VERSION "HIPBNYYYYYYYYYYYYYYYYYYYYYYYYYYYYYYYYYYYYY/4/%%%/4/'%**4YYY///"

NS_ :

BS_:

BU_: INV BMS VCU BMS Third_Party_Device BMS Third_Party_Device

BO_ 3221225472 VECTOR__INDEPENDENT_SIG_MSG: 0 Vector__XXX
 SG_ Thermistor_Module_Number : 0|8@1+ (1,0) [0|0] "" Vector__XXX
 SG_ Lowest_Thermistor_Value : 8|8@1- (1,0) [0|0] "c" Vector__XXX
 SG_ Highest_Thermistor_Value : 16|8@1- (1,0) [0|0] "c" Vector__XXX
 SG_ Average_Thermistor_Value : 24|8@1- (1,0) [0|0] "c" Vector__XXX
 SG_ Number_Thermistors_Enabled : 32|8@1+ (1,0) [0|0] "" Vector__XXX
 SG_ Highest_Thermistor_ID : 40|8@1+ (1,0) [0|0] "" Vector__XXX
 SG_ Lowest_Thermistor_ID : 48|8@1+ (1,0) [0|0] "" Vector__XXX
 SG_ Checksum : 56|8@1+ (1,0) [0|0] "" Vector__XXX
 SG_ Thermistor_Module_Number : 0|8@1+ (1,0) [0|0] "" Vector__XXX
 SG_ Lowest_Thermistor_Value : 8|8@1- (1,0) [0|0] "c" Vector__XXX
 SG_ Highest_Thermistor_Value : 16|8@1- (1,0) [0|0] "c" Vector__XXX
 SG_ Average_Thermistor_Value : 24|8@1- (1,0) [0|0] "c" Vector__XXX
 SG_ Number_Thermistors_Enabled : 32|8@1+ (1,0) [0|0] "" Vector__XXX
 SG_ Highest_Thermistor_ID : 40|8@1+ (1,0) [0|0] "" Vector__XXX
 SG_ Lowest_Thermistor_ID : 48|8@1+ (1,0) [0|0] "" Vector__XXX
 SG_ Checksum : 56|8@1+ (1,0) [0|0] "" Vector__XXX

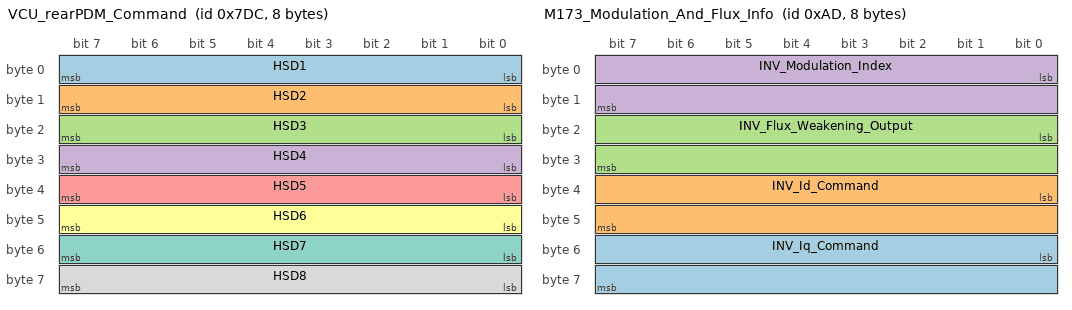
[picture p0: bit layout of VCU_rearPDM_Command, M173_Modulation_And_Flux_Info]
BO_ 2012 VCU_rearPDM_Command: 8 VCU
 SG_ HSD1 : 0|8@1+ (1,0) [0|1] "" Vector__XXX
 SG_ HSD2 : 8|8@1+ (1,0) [0|1] "" Vector__XXX
 SG_ HSD3 : 16|8@1+ (1,0) [0|1] "" Vector__XXX
 SG_ HSD4 : 24|8@1+ (1,0) [0|1] "" Vector__XXX
 SG_ HSD5 : 32|8@1+ (1,0) [0|1] "" Vector__XXX
 SG_ HSD6 : 40|8@1+ (1,0) [0|1] "" Vector__XXX
 SG_ HSD7 : 48|8@1+ (1,0) [0|1] "" Vector__XXX
 SG_ HSD8 : 56|8@1+ (1,0) [0|1] "" Vector__XXX

BO_ 173 M173_Modulation_And_Flux_Info: 8 INV
 SG_ INV_Iq_Command : 48|16@1- (0.1,0) [-3276.8|3276.7] "current:A" Vector__XXX
 SG_ INV_Id_Command : 32|16@1- (0.1,0) [-3276.8|3276.7] "current:A" Vector__XXX
 SG_ INV_Flux_Weakening_Output : 16|16@1- (0.1,0) [-3276.8|3276.7] "current:A" Vector__XXX
 SG_ INV_Modulation_Index : 0|16@1- (0.0001,0) [-3.2768|3.2767] "" Vector__XXX

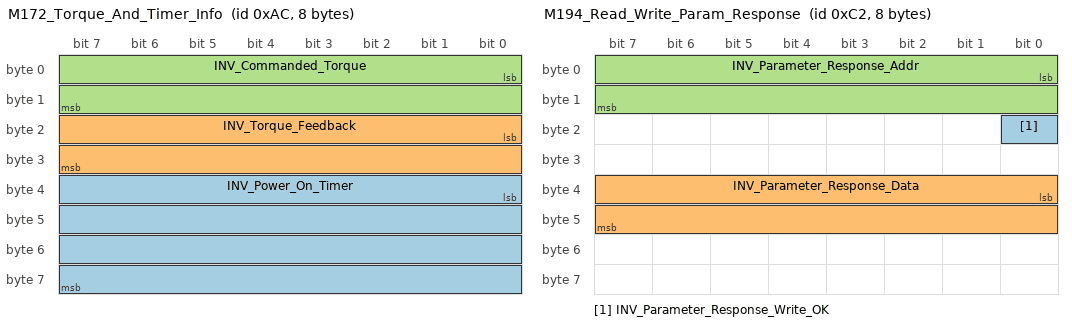
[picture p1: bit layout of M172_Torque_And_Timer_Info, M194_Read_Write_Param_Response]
BO_ 172 M172_Torque_And_Timer_Info: 8 INV
 SG_ INV_Power_On_Timer : 32|32@1+ (0.003,0) [0|12884800] "time:second" Vector__XXX
 SG_ INV_Torque_Feedback : 16|16@1- (0.1,0) [-3276.8|3276.7] "torque:N.m" Vector__XXX
 SG_ INV_Commanded_Torque : 0|16@1- (0.1,0) [-3276.8|3276.7] "torque:N.m" Vector__XXX

BO_ 194 M194_Read_Write_Param_Response: 8 INV
 SG_ INV_Parameter_Response_Write_OK : 16|1@1+ (1,0) [0|1] "" Vector__XXX
 SG_ INV_Parameter_Response_Data : 32|16@1- (1,0) [-32768|32767] "" Vector__XXX
 SG_ INV_Parameter_Response_Addr : 0|16@1+ (1,0) [0|65535] "" Vector__XXX

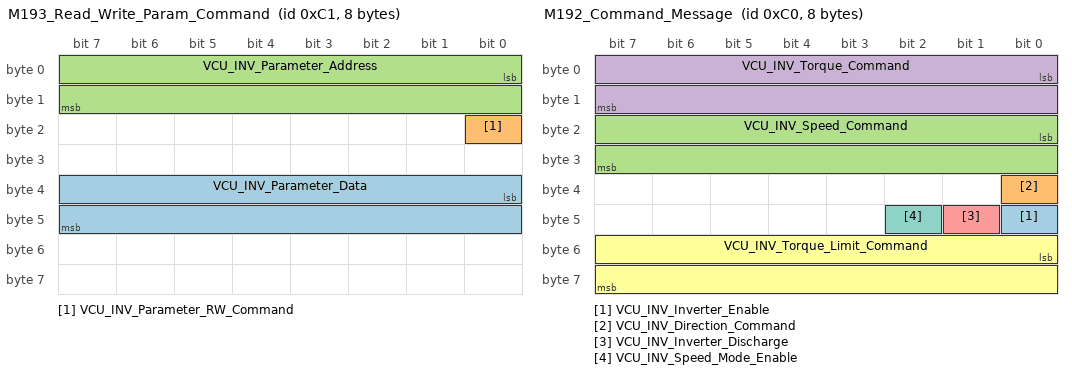
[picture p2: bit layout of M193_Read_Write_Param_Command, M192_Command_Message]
BO_ 193 M193_Read_Write_Param_Command: 8 VCU
 SG_ VCU_INV_Parameter_Data : 32|16@1- (1,0) [-32768|32767] "" Vector__XXX
 SG_ VCU_INV_Parameter_RW_Command : 16|1@1+ (1,0) [0|1] "" Vector__XXX
 SG_ VCU_INV_Parameter_Address : 0|16@1+ (1,0) [0|65535] "" Vector__XXX

BO_ 192 M192_Command_Message: 8 VCU
 SG_ VCU_INV_Inverter_Enable : 40|1@1+ (1,0) [0|1] "" Vector__XXX
 SG_ VCU_INV_Direction_Command : 32|1@1+ (1,0) [0|1] "" Vector__XXX
 SG_ VCU_INV_Speed_Command : 16|16@1- (1,0) [-32768|32767] "angular_speed:rpm" Vector__XXX
 SG_ VCU_INV_Torque_Command : 0|16@1- (0.1,0) [-3276.8|3276.7] "torque:N.m" Vector__XXX
 SG_ VCU_INV_Inverter_Discharge : 41|1@1+ (1,0) [0|1] "" Vector__XXX
 SG_ VCU_INV_Torque_Limit_Command : 48|16@1- (0.1,0) [-3276.8|3276.7] "torque:N.m" Vector__XXX
 SG_ VCU_INV_Speed_Mode_Enable : 42|1@1+ (1,0) [0|1] "" Vector__XXX

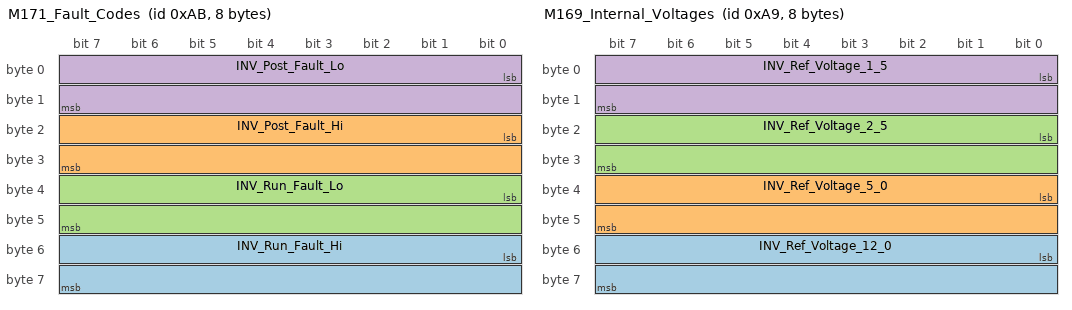
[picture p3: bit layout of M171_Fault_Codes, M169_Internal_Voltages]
BO_ 171 M171_Fault_Codes: 8 INV
 SG_ INV_Run_Fault_Hi : 48|16@1+ (1,0) [0|65535] "" Vector__XXX
 SG_ INV_Post_Fault_Hi : 16|16@1+ (1,0) [0|65535] "" Vector__XXX
 SG_ INV_Run_Fault_Lo : 32|16@1+ (1,0) [0|65535] "" Vector__XXX
 SG_ INV_Post_Fault_Lo : 0|16@1+ (1,0) [0|65535] "" Vector__XXX

BO_ 170 M170_Internal_States: 8 INV
 SG_ INV_Direction_Command : 56|1@1+ (1,0) [0|1] "" Vector__XXX
 SG_ INV_Inverter_Enable_State : 48|1@1+ (1,0) [0|1] "" Vector__XXX
 SG_ INV_Relay_3_Status : 26|1@1+ (1,0) [0|1] "" Vector__XXX
 SG_ INV_Relay_4_Status : 27|1@1+ (1,0) [0|1] "" Vector__XXX
 SG_ INV_Relay_2_Status : 25|1@1+ (1,0) [0|1] "" Vector__XXX
 SG_ INV_Inverter_Run_Mode : 32|1@1+ (1,0) [0|1] "" Vector__XXX
 SG_ INV_Inverter_Command_Mode : 40|1@1+ (1,0) [0|1] "" Vector__XXX
 SG_ INV_Relay_1_Status : 24|1@1+ (1,0) [0|1] "" Vector__XXX
 SG_ INV_Inverter_State : 16|8@1+ (1,0) [0|255] "" Vector__XXX
 SG_ INV_VSM_State : 0|8@1+ (1,0) [0|15] "" Vector__XXX
 SG_ INV_Inverter_Enable_Lockout : 55|1@1+ (1,0) [0|1] "" Vector__XXX
 SG_ INV_Inverter_Discharge_State : 37|3@1+ (1,0) [0|7] "" Vector__XXX
 SG_ INV_Relay_5_Status : 28|1@1+ (1,0) [0|1] "" Vector__XXX
 SG_ INV_Relay_6_Status : 29|1@1+ (1,0) [0|1] "" Vector__XXX
 SG_ INV_BMS_Active : 57|1@1+ (1,0) [0|1] "" Vector__XXX
 SG_ INV_BMS_Torque_Limiting : 58|1@1+ (1,0) [0|1] "" Vector__XXX
 SG_ INV_PWM_Frequency : 8|8@1+ (1,0) [0|255] "" Vector__XXX
 SG_ INV_Limit_Max_Speed : 59|1@1+ (1,0) [0|1] "" Vector__XXX
 SG_ INV_Limit_Hot_Spot : 60|1@1+ (1,0) [0|1] "" Vector__XXX
 SG_ INV_Low_Speed_Limiting : 61|1@1+ (1,0) [0|1] "" Vector__XXX
 SG_ INV_Rolling_Counter : 44|4@1+ (1,0) [0|15] "" Vector__XXX
 SG_ INV_Limit_Coolant_Derating : 62|1@1+ (1,0) [0|1] "" Vector__XXX
 SG_ INV_Self_Sensing_Assist_Enable : 33|1@1+ (1,0) [0|1] "" Vector__XXX
 SG_ INV_Limit_Stall_Burst_Model : 63|1@1+ (1,0) [0|1] "" Vector__XXX
 SG_ INV_Burst_Model_Mode : 49|1@1+ (1,0) [0|1] "" Vector__XXX
 SG_ INV_Key_Switch_Start_Status : 54|1@1+ (1,0) [0|1] "" Vector__XXX

BO_ 169 M169_Internal_Voltages: 8 INV
 SG_ INV_Ref_Voltage_12_0 : 48|16@1- (0.01,0) [-327.68|327.67] "voltage:V" Vector__XXX
 SG_ INV_Ref_Voltage_5_0 : 32|16@1- (0.01,0) [-327.68|327.67] "voltage:V" Vector__XXX
 SG_ INV_Ref_Voltage_2_5 : 16|16@1- (0.01,0) [-327.68|327.67] "voltage:V" Vector__XXX
 SG_ INV_Ref_Voltage_1_5 : 0|16@1- (0.01,0) [-327.68|327.67] "voltage:V" Vector__XXX

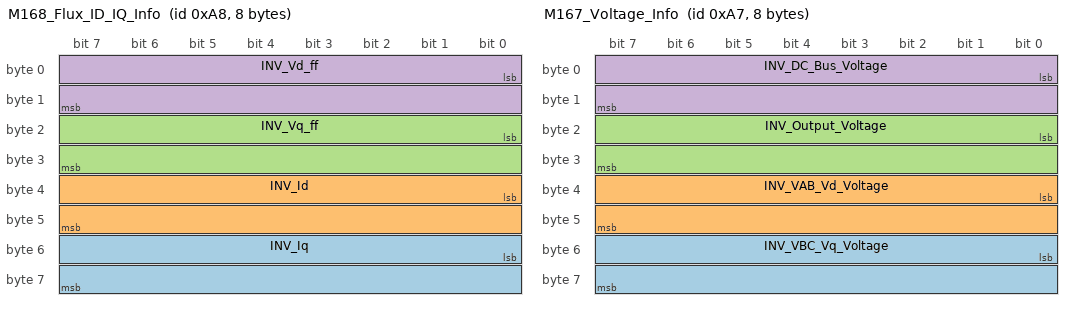
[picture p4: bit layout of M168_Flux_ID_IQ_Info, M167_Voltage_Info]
BO_ 168 M168_Flux_ID_IQ_Info: 8 INV
 SG_ INV_Iq : 48|16@1- (0.1,0) [-3276.8|3276.7] "current:A" Vector__XXX
 SG_ INV_Id : 32|16@1- (0.1,0) [-3276.8|3276.7] "current:A" Vector__XXX
 SG_ INV_Vq_ff : 16|16@1- (0.1,0) [-3276.7|3276.7] "voltage:V" Vector__XXX
 SG_ INV_Vd_ff : 0|16@1- (0.1,0) [-3276.7|3276.7] "voltage:V" Vector__XXX

BO_ 167 M167_Voltage_Info: 8 INV
 SG_ INV_VBC_Vq_Voltage : 48|16@1- (0.1,0) [-3276.8|3276.7] "voltage:V" Vector__XXX
 SG_ INV_VAB_Vd_Voltage : 32|16@1- (0.1,0) [-3276.8|3276.7] "voltage:V" Vector__XXX
 SG_ INV_Output_Voltage : 16|16@1- (0.1,0) [-3276.8|3276.7] "voltage:V" Vector__XXX
 SG_ INV_DC_Bus_Voltage : 0|16@1- (0.1,0) [-3276.8|3276.7] "voltage:V" Vector__XXX

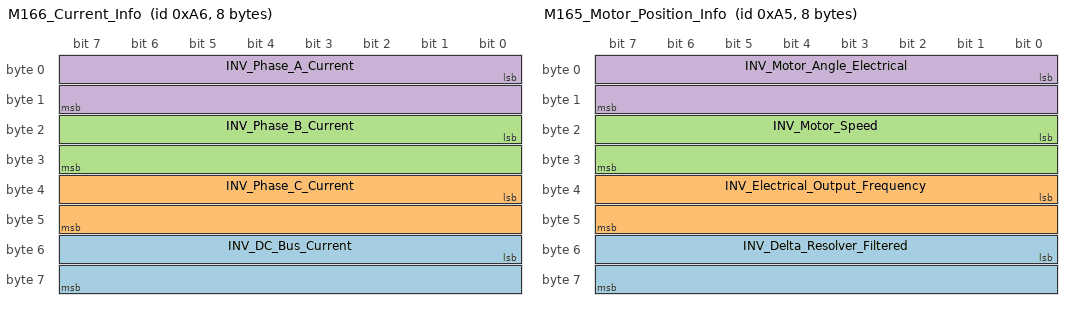
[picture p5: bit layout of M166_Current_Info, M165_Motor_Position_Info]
BO_ 166 M166_Current_Info: 8 INV
 SG_ INV_DC_Bus_Current : 48|16@1- (0.1,0) [-3276.8|3276.7] "current:A" Vector__XXX
 SG_ INV_Phase_C_Current : 32|16@1- (0.1,0) [-3276.8|3276.7] "current:A" Vector__XXX
 SG_ INV_Phase_B_Current : 16|16@1- (0.1,0) [-3276.8|3276.7] "current:A" Vector__XXX
 SG_ INV_Phase_A_Current : 0|16@1- (0.1,0) [-3276.8|3276.7] "current:A" Vector__XXX

BO_ 165 M165_Motor_Position_Info: 8 INV
 SG_ INV_Delta_Resolver_Filtered : 48|16@1- (0.1,0) [-3276.8|3276.7] "angle:deg" Vector__XXX
 SG_ INV_Electrical_Output_Frequency : 32|16@1- (0.1,0) [-3276.8|3276.7] "frequency:Hz" Vector__XXX
 SG_ INV_Motor_Speed : 16|16@1- (1,0) [-32768|32767] "angular_speed:rpm" Vector__XXX
 SG_ INV_Motor_Angle_Electrical : 0|16@1+ (0.1,0) [0|6553.5] "angle:deg" Vector__XXX

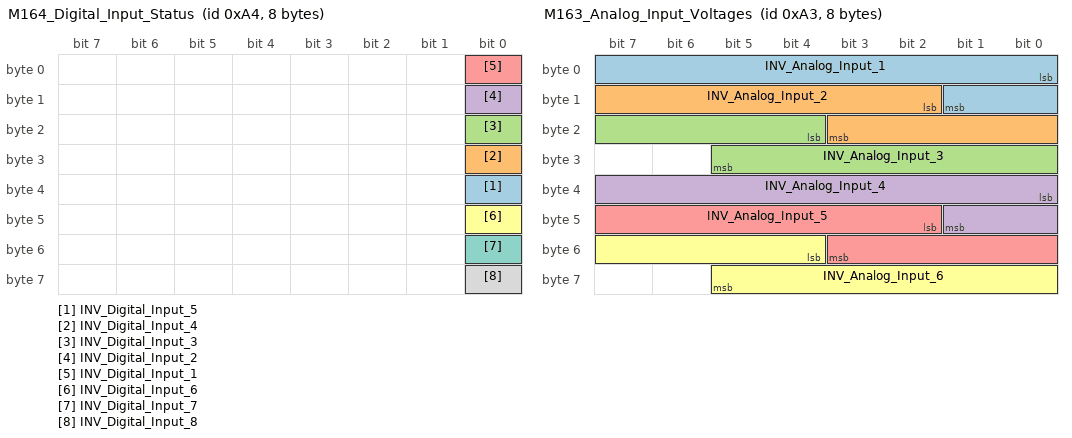
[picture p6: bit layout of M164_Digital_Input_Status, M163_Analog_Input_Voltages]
BO_ 164 M164_Digital_Input_Status: 8 INV
 SG_ INV_Digital_Input_5 : 32|1@1+ (1,0) [0|1] "" Vector__XXX
 SG_ INV_Digital_Input_4 : 24|1@1+ (1,0) [0|1] "" Vector__XXX
 SG_ INV_Digital_Input_3 : 16|1@1+ (1,0) [0|1] "" Vector__XXX
 SG_ INV_Digital_Input_2 : 8|1@1+ (1,0) [0|1] "" Vector__XXX
 SG_ INV_Digital_Input_1 : 0|1@1+ (1,0) [0|1] "" Vector__XXX
 SG_ INV_Digital_Input_6 : 40|1@1+ (1,0) [0|1] "" Vector__XXX
 SG_ INV_Digital_Input_7 : 48|1@1+ (1,0) [0|1] "" Vector__XXX
 SG_ INV_Digital_Input_8 : 56|1@1+ (1,0) [0|1] "" Vector__XXX

BO_ 163 M163_Analog_Input_Voltages: 8 INV
 SG_ INV_Analog_Input_1 : 0|10@1+ (0.01,0) [0|10.23] "voltage:V" Vector__XXX
 SG_ INV_Analog_Input_2 : 10|10@1+ (0.01,0) [0|10.23] "voltage:V" Vector__XXX
 SG_ INV_Analog_Input_3 : 20|10@1+ (0.01,0) [0|10.23] "voltage:V" Vector__XXX
 SG_ INV_Analog_Input_4 : 32|10@1+ (0.01,0) [0|10.23] "voltage:V" Vector__XXX
 SG_ INV_Analog_Input_5 : 42|10@1+ (0.01,0) [0|10.23] "voltage:V" Vector__XXX
 SG_ INV_Analog_Input_6 : 52|10@1+ (0.01,0) [0|10.23] "voltage:V" Vector__XXX

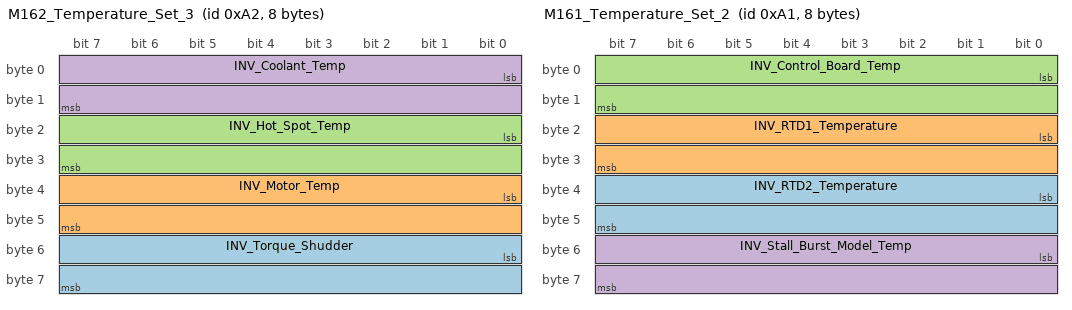
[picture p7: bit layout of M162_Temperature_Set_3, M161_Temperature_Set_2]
BO_ 162 M162_Temperature_Set_3: 8 INV
 SG_ INV_Torque_Shudder : 48|16@1- (0.1,0) [-3276.8|3276.7] "torque:N.m" Vector__XXX
 SG_ INV_Motor_Temp : 32|16@1- (0.1,0) [-3276.8|3276.7] "temperature:C" Vector__XXX
 SG_ INV_Hot_Spot_Temp : 16|16@1- (0.1,0) [-3276.8|3276.7] "temperature:C" Vector__XXX
 SG_ INV_Coolant_Temp : 0|16@1- (0.1,0) [-3276.8|3276.7] "temperature:C" Vector__XXX

BO_ 161 M161_Temperature_Set_2: 8 INV
 SG_ INV_RTD2_Temperature : 32|16@1- (0.1,0) [-3276.8|3276.7] "temperature:C" Vector__XXX
 SG_ INV_RTD1_Temperature : 16|16@1- (0.1,0) [-3276.8|3276.7] "temperature:C" Vector__XXX
 SG_ INV_Control_Board_Temp : 0|16@1- (0.1,0) [-3276.8|3276.7] "temperature:C" Vector__XXX
 SG_ INV_Stall_Burst_Model_Temp : 48|16@1- (0.1,0) [-3276.8|3276.7] "temperature:C" Vector__XXX

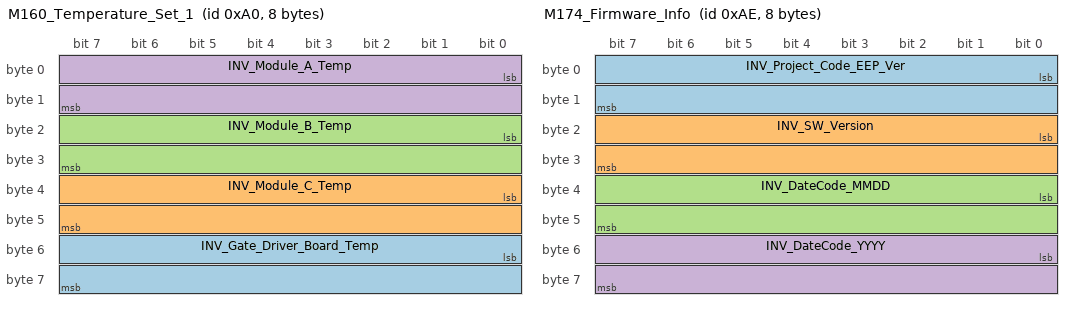
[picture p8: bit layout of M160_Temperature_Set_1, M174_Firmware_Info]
BO_ 160 M160_Temperature_Set_1: 8 INV
 SG_ INV_Gate_Driver_Board_Temp : 48|16@1- (0.1,0) [-3276.8|3276.7] "temperature:C" Vector__XXX
 SG_ INV_Module_C_Temp : 32|16@1- (0.1,0) [-3276.8|3276.7] "temperature:C" Vector__XXX
 SG_ INV_Module_B_Temp : 16|16@1- (0.1,0) [-3276.8|3276.7] "temperature:C" Vector__XXX
 SG_ INV_Module_A_Temp : 0|16@1- (0.1,0) [-3276.8|3276.7] "temperature:C" Vector__XXX

BO_ 174 M174_Firmware_Info: 8 INV
 SG_ INV_Project_Code_EEP_Ver : 0|16@1+ (1,0) [0|65535] "" Vector__XXX
 SG_ INV_SW_Version : 16|16@1+ (1,0) [0|65535] "" Vector__XXX
 SG_ INV_DateCode_MMDD : 32|16@1+ (1,0) [0|65535] "" Vector__XXX
 SG_ INV_DateCode_YYYY : 48|16@1+ (1,0) [0|65535] "" Vector__XXX

BO_ 175 M175_Diag_Data_Message: 8 INV
 SG_ INV_Diag_Record : 0|8@1+ (1,0) [0|160] "" Vector__XXX
 SG_ INV_Diag_Segment M : 8|8@1+ (1,0) [0|5] "" Vector__XXX
 SG_ INV_Diag_Gamma_Resolver m0 : 16|16@1- (0.1,0) [0|360] "angle:deg" Vector__XXX
 SG_ INV_Diag_Gamma_Observer m0 : 32|16@1- (0.1,0) [0|360] "angle:deg" Vector__XXX
 SG_ INV_Diag_Sin_Used m0 : 48|16@1- (1,0) [-5|5] "voltage:V" Vector__XXX
 SG_ INV_Diag_Cos_Used m1 : 16|16@1- (1,0) [-5|5] "voltage:V" Vector__XXX
 SG_ INV_Diag_Ia m1 : 32|16@1- (0.1,0) [-2000|2000] "current:A" Vector__XXX
 SG_ INV_Diag_Ib m1 : 48|16@1- (0.1,0) [-2000|2000] "current:A" Vector__XXX
 SG_ INV_Diag_Ic m2 : 16|16@1- (0.1,0) [-2000|2000] "current:A" Vector__XXX
 SG_ INV_Diag_Vdc m2 : 32|16@1- (0.1,0) [0|1000] "voltage:V" Vector__XXX
 SG_ INV_Diag_Iq_cmd m2 : 48|16@1- (0.1,0) [-2000|2000] "current:A" Vector__XXX
 SG_ INV_Diag_Id_cmd m3 : 16|16@1- (0.1,0) [-2000|2000] "current:A" Vector__XXX
 SG_ INV_Diag_Mod_Index m3 : 32|16@1- (0.0001,0) [0|2] "" Vector__XXX
 SG_ INV_Diag_FW_Output m3 : 48|16@1- (0.1,0) [-2000|2000] "current:A" Vector__XXX
 SG_ INV_Diag_Vq_Cmd m4 : 16|16@1- (0.1,0) [-1000|1000] "voltage:V" Vector__XXX
 SG_ INV_Diag_Vd_Cmd m4 : 32|16@1- (0.1,0) [-1000|1000] "voltage:V" Vector__XXX
 SG_ INV_Diag_Vqs_Cmd m4 : 48|16@1- (0.1,0) [-1000|1000] "voltage:V" Vector__XXX
 SG_ INV_Diag_PWM_Freq m5 : 16|16@1+ (1,0) [0|24] "frequency:kHz" Vector__XXX
 SG_ INV_Diag_Run_Faults_Lo m5 : 32|16@1+ (1,0) [0|65535] "" Vector__XXX
 SG_ INV_Diag_Run_Faults_Hi m5 : 48|16@1+ (1,0) [0|65535] "" Vector__XXX

BO_ 514 BMS_Current_Limit: 8 BMS
 SG_ BMS_Max_Discharge_Current : 0|16@1+ (1,0) [0|1000] "current:A" Vector__XXX
 SG_ BMS_Max_Charge_Current : 16|16@1+ (1,0) [0|1000] "current:A" Vector__XXX

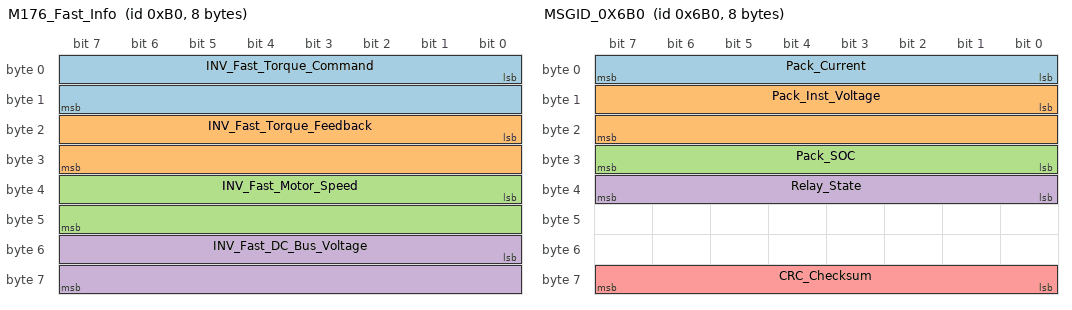
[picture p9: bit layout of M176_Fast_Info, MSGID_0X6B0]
BO_ 176 M176_Fast_Info: 8 INV
 SG_ INV_Fast_Torque_Command : 0|16@1- (0.1,0) [-3276.8|32767.7] "torque:N.m" Vector__XXX
 SG_ INV_Fast_Torque_Feedback : 16|16@1- (0.1,0) [-3276.8|3276.7] "torque:N.m" Vector__XXX
 SG_ INV_Fast_Motor_Speed : 32|16@1- (1,0) [-32768|32767] "angular_speed:rpm" Vector__XXX
 SG_ INV_Fast_DC_Bus_Voltage : 48|16@1- (0.1,0) [-3276.8|3276.7] "voltage:V" Vector__XXX

BO_ 1712 MSGID_0X6B0: 8 BMS
 SG_ Pack_Current : 0|8@1+ (0.1,0) [0|0] "Amps"  Third_Party_Device
 SG_ Pack_Inst_Voltage : 8|16@1+ (0.1,0) [0|0] "Volts"  Third_Party_Device
 SG_ Pack_SOC : 24|8@1+ (0.5,0) [0|0] "Percent"  Third_Party_Device
 SG_ Relay_State : 32|8@1+ (1,0) [0|0] ""  Third_Party_Device
 SG_ CRC_Checksum : 56|8@1+ (1,1720) [0|0] ""  Third_Party_Device

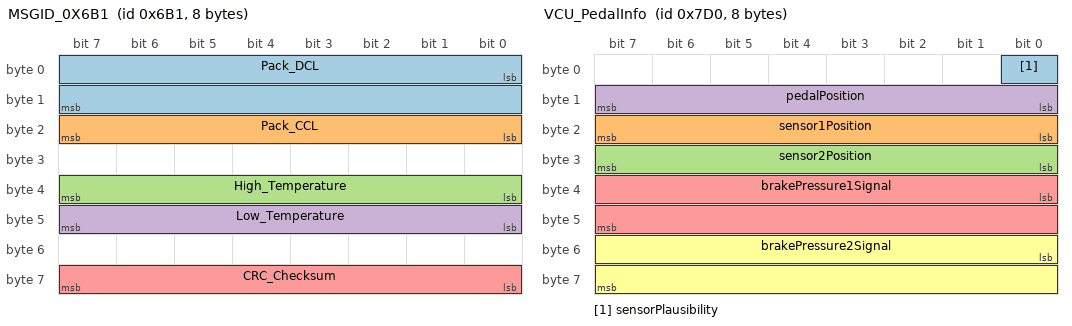
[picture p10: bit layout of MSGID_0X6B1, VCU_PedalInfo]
BO_ 1713 MSGID_0X6B1: 8 BMS
 SG_ Pack_DCL : 0|16@1+ (1,0) [0|0] "Amps"  Third_Party_Device
 SG_ Pack_CCL : 16|8@1+ (1,0) [0|0] "Amps"  Third_Party_Device
 SG_ High_Temperature : 32|8@1+ (1,0) [0|0] "Celsius"  Third_Party_Device
 SG_ Low_Temperature : 40|8@1+ (1,0) [0|0] "Celsius"  Third_Party_Device
 SG_ CRC_Checksum : 56|8@1+ (1,1721) [0|0] ""  Third_Party_Device

BO_ 1714 MSGID_0X6B2: 4 BMS
 SG_ DTC_Flags_1 : 7|16@0+ (1,0) [0|0] ""  Third_Party_Device
 SG_ DTC_Flags_2 : 23|16@0+ (1,0) [0|0] ""  Third_Party_Device

BO_ 2000 VCU_PedalInfo: 8 VCU
 SG_ sensorPlausibility : 0|1@1+ (1,0) [2|1] "" Vector__XXX
 SG_ sensor1Position : 16|8@1+ (1,0) [0|100] "" Vector__XXX
 SG_ sensor2Position : 24|8@1+ (1,0) [0|100] "" Vector__XXX
 SG_ pedalPosition : 8|8@1+ (1,0) [0|100] "" Vector__XXX
 SG_ brakePressure1Signal : 32|16@1+ (0.01,0) [0|5] "" Vector__XXX
 SG_ brakePressure2Signal : 48|16@1+ (0.01,0) [0|5] "" Vector__XXX

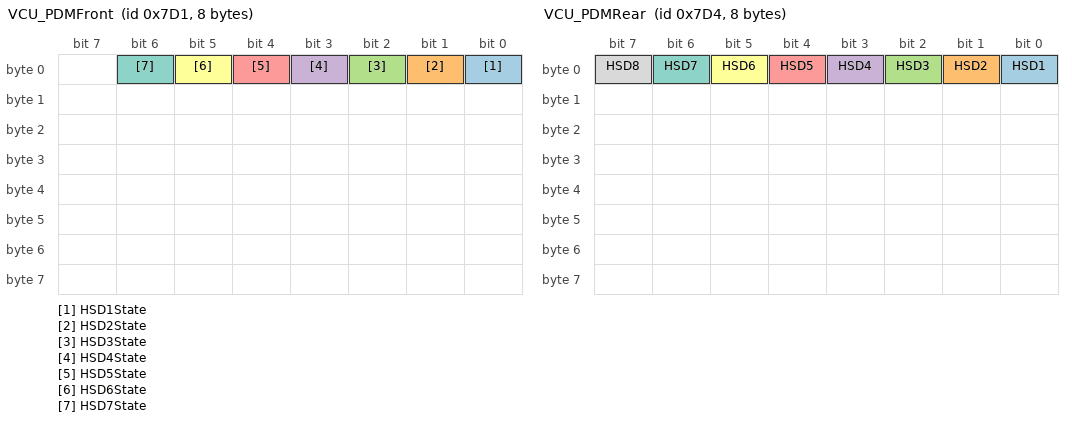
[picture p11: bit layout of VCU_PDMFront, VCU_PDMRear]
BO_ 2001 VCU_PDMFront: 8 VCU
 SG_ HSD1State : 0|1@1+ (1,0) [0|1] "" Vector__XXX
 SG_ HSD2State : 1|1@1+ (1,0) [0|0] "" Vector__XXX
 SG_ HSD3State : 2|1@1+ (1,0) [0|0] "" Vector__XXX
 SG_ HSD4State : 3|1@1+ (1,0) [0|0] "" Vector__XXX
 SG_ HSD5State : 4|1@1+ (1,0) [0|0] "" Vector__XXX
 SG_ HSD6State : 5|1@1+ (1,0) [0|0] "" Vector__XXX
 SG_ HSD7State : 6|1@1+ (1,0) [0|0] "" Vector__XXX

BO_ 2002 VCU_State_Info: 8 VCU
 SG_ State : 8|8@1+ (1,0) [0|6] "" Vector__XXX
 SG_ RTD_Button : 0|1@1+ (1,0) [0|1] "" Vector__XXX

BO_ 2003 VCU_Precharge: 8 VCU
 SG_ Precharge_Enable : 0|1@1+ (1,0) [0|1] "" Vector__XXX
 SG_ Precharge_OK : 1|1@1+ (1,0) [0|1] "" Vector__XXX

BO_ 2004 VCU_PDMRear: 8 VCU
 SG_ HSD1 : 0|1@1+ (1,0) [0|1] "" Vector__XXX
 SG_ HSD2 : 1|1@1+ (1,0) [0|1] "" Vector__XXX
 SG_ HSD3 : 2|1@1+ (1,0) [0|1] "" Vector__XXX
 SG_ HSD4 : 3|1@1+ (1,0) [0|1] "" Vector__XXX
 SG_ HSD5 : 4|1@1+ (1,0) [0|1] "" Vector__XXX
 SG_ HSD6 : 5|1@1+ (1,0) [0|1] "" Vector__XXX
 SG_ HSD7 : 6|1@1+ (1,0) [0|1] "" Vector__XXX
 SG_ HSD8 : 7|1@1+ (1,0) [0|0] "" Vector__XXX

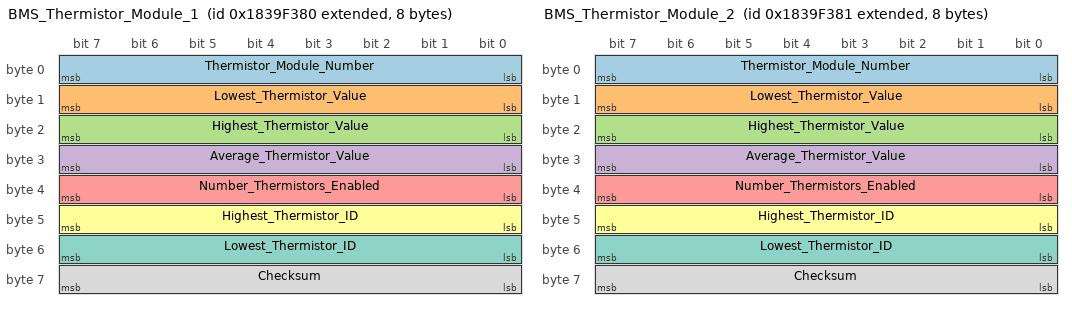
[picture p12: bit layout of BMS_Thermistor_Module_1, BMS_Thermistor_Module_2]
BO_ 2553934720 BMS_Thermistor_Module_1: 8 BMS
 SG_ Thermistor_Module_Number : 0|8@1+ (1,0) [0|0] "" Vector__XXX
 SG_ Lowest_Thermistor_Value : 8|8@1- (1,0) [0|0] "c" Vector__XXX
 SG_ Highest_Thermistor_Value : 16|8@1- (1,0) [0|0] "c" Vector__XXX
 SG_ Average_Thermistor_Value : 24|8@1- (1,0) [0|0] "c" Vector__XXX
 SG_ Number_Thermistors_Enabled : 32|8@1+ (1,0) [0|0] "" Vector__XXX
 SG_ Highest_Thermistor_ID : 40|8@1+ (1,0) [0|0] "" Vector__XXX
 SG_ Lowest_Thermistor_ID : 48|8@1+ (1,0) [0|0] "" Vector__XXX
 SG_ Checksum : 56|8@1+ (1,0) [0|0] "" Vector__XXX

BO_ 2553934721 BMS_Thermistor_Module_2: 8 BMS
 SG_ Thermistor_Module_Number : 0|8@1+ (1,0) [0|0] "" Vector__XXX
 SG_ Lowest_Thermistor_Value : 8|8@1- (1,0) [0|0] "c" Vector__XXX
 SG_ Highest_Thermistor_Value : 16|8@1- (1,0) [0|0] "c" Vector__XXX
 SG_ Average_Thermistor_Value : 24|8@1- (1,0) [0|0] "c" Vector__XXX
 SG_ Number_Thermistors_Enabled : 32|8@1+ (1,0) [0|0] "" Vector__XXX
 SG_ Highest_Thermistor_ID : 40|8@1+ (1,0) [0|0] "" Vector__XXX
 SG_ Lowest_Thermistor_ID : 48|8@1+ (1,0) [0|0] "" Vector__XXX
 SG_ Checksum : 56|8@1+ (1,0) [0|0] "" Vector__XXX

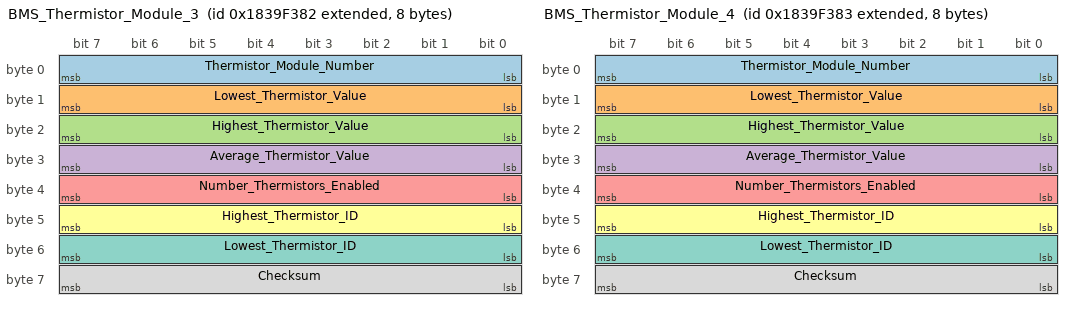
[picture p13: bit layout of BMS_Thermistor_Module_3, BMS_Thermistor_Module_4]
BO_ 2553934722 BMS_Thermistor_Module_3: 8 BMS
 SG_ Thermistor_Module_Number : 0|8@1+ (1,0) [0|0] "" Vector__XXX
 SG_ Lowest_Thermistor_Value : 8|8@1- (1,0) [0|0] "c" Vector__XXX
 SG_ Highest_Thermistor_Value : 16|8@1- (1,0) [0|0] "c" Vector__XXX
 SG_ Average_Thermistor_Value : 24|8@1- (1,0) [0|0] "c" Vector__XXX
 SG_ Number_Thermistors_Enabled : 32|8@1+ (1,0) [0|0] "" Vector__XXX
 SG_ Highest_Thermistor_ID : 40|8@1+ (1,0) [0|0] "" Vector__XXX
 SG_ Lowest_Thermistor_ID : 48|8@1+ (1,0) [0|0] "" Vector__XXX
 SG_ Checksum : 56|8@1+ (1,0) [0|0] "" Vector__XXX

BO_ 2553934723 BMS_Thermistor_Module_4: 8 BMS
 SG_ Thermistor_Module_Number : 0|8@1+ (1,0) [0|0] "" Vector__XXX
 SG_ Lowest_Thermistor_Value : 8|8@1- (1,0) [0|0] "c" Vector__XXX
 SG_ Highest_Thermistor_Value : 16|8@1- (1,0) [0|0] "c" Vector__XXX
 SG_ Average_Thermistor_Value : 24|8@1- (1,0) [0|0] "c" Vector__XXX
 SG_ Number_Thermistors_Enabled : 32|8@1+ (1,0) [0|0] "" Vector__XXX
 SG_ Highest_Thermistor_ID : 40|8@1+ (1,0) [0|0] "" Vector__XXX
 SG_ Lowest_Thermistor_ID : 48|8@1+ (1,0) [0|0] "" Vector__XXX
 SG_ Checksum : 56|8@1+ (1,0) [0|0] "" Vector__XXX

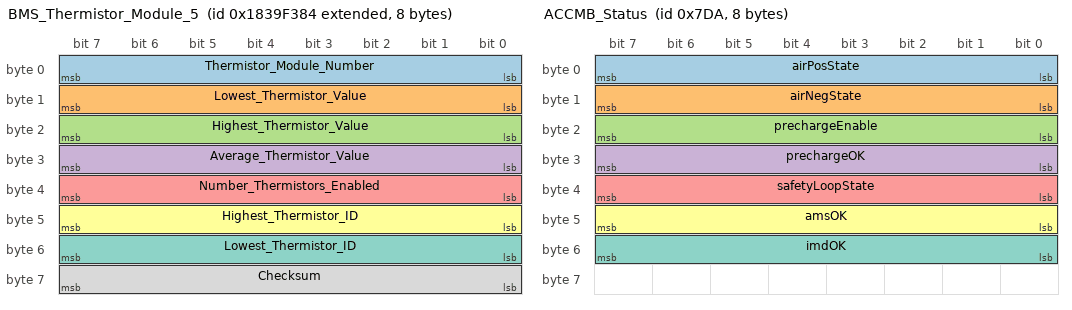
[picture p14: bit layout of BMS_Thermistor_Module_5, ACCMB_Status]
BO_ 2553934724 BMS_Thermistor_Module_5: 8 BMS
 SG_ Thermistor_Module_Number : 0|8@1+ (1,0) [0|0] "" Vector__XXX
 SG_ Lowest_Thermistor_Value : 8|8@1- (1,0) [0|0] "c" Vector__XXX
 SG_ Highest_Thermistor_Value : 16|8@1- (1,0) [0|0] "c" Vector__XXX
 SG_ Average_Thermistor_Value : 24|8@1- (1,0) [0|0] "c" Vector__XXX
 SG_ Number_Thermistors_Enabled : 32|8@1+ (1,0) [0|0] "" Vector__XXX
 SG_ Highest_Thermistor_ID : 40|8@1+ (1,0) [0|0] "" Vector__XXX
 SG_ Lowest_Thermistor_ID : 48|8@1+ (1,0) [0|0] "" Vector__XXX
 SG_ Checksum : 56|8@1+ (1,0) [0|0] "" Vector__XXX

BO_ 2010 ACCMB_Status: 8 BMS
 SG_ airPosState : 0|8@1+ (1,0) [0|0] "" Vector__XXX
 SG_ airNegState : 8|8@1+ (1,0) [0|0] "" Vector__XXX
 SG_ prechargeEnable : 16|8@1+ (1,0) [0|0] "" Vector__XXX
 SG_ prechargeOK : 24|8@1+ (1,0) [0|0] "" Vector__XXX
 SG_ safetyLoopState : 32|8@1+ (1,0) [0|0] "" Vector__XXX
 SG_ amsOK : 40|8@1+ (1,0) [0|0] "" Vector__XXX
 SG_ imdOK : 48|8@1+ (1,0) [0|0] "" Vector__XXX

BO_ 2011 VCU_BrakeLight: 1 VCU
 SG_ BrakeLightSignal : 0|1@1+ (1,0) [0|1] "" Vector__XXX

BO_ 2013 VCU_rearLinPots: 8 VCU

BO_ 2028 VCU_Front_Wheel_Left: 2 VCU
 SG_ Front_Left_Wheelspeed : 0|16@1+ (0.1,0) [0|6553.5] "RPM" Vector__XXX

BO_ 2029 VCU_Front_Wheel_Right: 2 VCU
 SG_ Front_Right_Wheelspeed : 0|16@1+ (0.1,0) [0|6553.5] "RPM" Vector__XXX

BO_ 177 M177_Torque_Capability: 8 INV
 SG_ INV_Torque_Capability : 0|16@1+ (0.1,0) [0|0] "" Vector__XXX

CM_ SG_ 173 INV_Iq_Command "The commanded Q-axis current";
CM_ SG_ 173 INV_Id_Command "The commanded D-axis current";
CM_ SG_ 173 INV_Flux_Weakening_Output "This is the current output of the flux regulator.";
CM_ SG_ 173 INV_Modulation_Index "This is the modulation index. The scale factor is x100. To get the actual modulation index divide the value by 100.";
CM_ SG_ 172 INV_Power_On_Timer "Updated every 3 msec. This will roll over in approximately 150 days!";
CM_ SG_ 172 INV_Torque_Feedback "Estimated motor torque feedback";
CM_ SG_ 172 INV_Commanded_Torque "The commanded Torque";
CM_ BO_ 194 "To write a parameter use message 0x0C1 with byte #2 set to 1 (write). 
To read a parameter use message 0x0C1 with byte #2 to set 0 (read). ";
CM_ SG_ 194 INV_Parameter_Response_Write_OK "0=Write failure, 1=Success";
CM_ SG_ 194 INV_Parameter_Response_Data "Data from parameter message.  All data is 16 bits and is contained in bytes 4 and 5. Bytes 6 and 7 should be ignored.";
CM_ SG_ 194 INV_Parameter_Response_Addr "Address of parameter response message data.";
CM_ BO_ 193 "To write a parameter use message 0x0C1 with byte #2 set to 1 (write). 
To read a parameter use message 0x0C1 with byte #2 to set 0 (read). ";
CM_ SG_ 193 VCU_INV_Parameter_Data "Data to be written.  All data is 16 bits and is contained in bytes 4 and 5.";
CM_ SG_ 193 VCU_INV_Parameter_RW_Command "0=Read, 1=Write";
CM_ SG_ 193 VCU_INV_Parameter_Address "Address of parameter to be written or read.";
CM_ BO_ 192 "The command message is used to transmit data to the controller. This message is sent from a user supplied external controller to the PMxxx controller.";
CM_ SG_ 192 VCU_INV_Inverter_Enable "0=Inverter OFF, 1 = Inverter ON";
CM_ SG_ 192 VCU_INV_Direction_Command "0=Reverse, 1=Forward.  Forward is positive motor speed.";
CM_ SG_ 192 VCU_INV_Speed_Command "Speed command used when in speed mode";
CM_ SG_ 192 VCU_INV_Torque_Command "Torque command when in torque mode";
CM_ SG_ 192 VCU_INV_Inverter_Discharge "0=Discharge Disable,1=Discharge Enable";
CM_ SG_ 192 VCU_INV_Torque_Limit_Command "Torque Limit, set to 0 to keep default";
CM_ SG_ 192 VCU_INV_Speed_Mode_Enable "0 = No change to mode, 1 = change to speed mode from torque mode";
CM_ SG_ 171 INV_Run_Fault_Hi "Each bit represents a fault. Please refer to PM100 Users Manual for details.";
CM_ SG_ 171 INV_Post_Fault_Hi "Each bit represents a fault. Please refer to PM100 Users Manual for details.";
CM_ SG_ 171 INV_Run_Fault_Lo "Each bit represents a fault. Please refer to PM100 Users Manual for details.";
CM_ SG_ 171 INV_Post_Fault_Lo "Each bit represents a fault. Please refer to PM100 Users Manual for details.";
CM_ SG_ 170 INV_Direction_Command "1 = Forward
0 = 'Reverse' if inverter enabled  & 'Stopped' if inverter is disabled";
CM_ SG_ 170 INV_Inverter_Enable_State "0=Inverter Disabled, 
1=Inverter Enabled";
CM_ SG_ 170 INV_Relay_3_Status "0=OFF, 1=ON";
CM_ SG_ 170 INV_Relay_4_Status "0=OFF, 1=ON";
CM_ SG_ 170 INV_Relay_2_Status "0=OFF, 1=ON";
CM_ SG_ 170 INV_Inverter_Run_Mode "0=Torque Mode, 1=Speed Mode";
CM_ SG_ 170 INV_Inverter_Command_Mode "0=CAN mode, 1=VSM mode";
CM_ SG_ 170 INV_Relay_1_Status "0=OFF, 1=ON";
CM_ SG_ 170 INV_Inverter_State "Different states for the inverter state machine";
CM_ SG_ 170 INV_VSM_State "Different states for the vehicle state machine";
CM_ SG_ 170 INV_Inverter_Enable_Lockout "0=Lockout Disabled, 1=Lockout Enabled";
CM_ SG_ 170 INV_Inverter_Discharge_State "0 = Disabled, 1 = Enabled, 2 = Speed Check, 3 = Active, 4 = Complete, 5 = Error, 6 = Override, 7 = Timeout";
CM_ SG_ 170 INV_Relay_5_Status "0=OFF, 1=ON";
CM_ SG_ 170 INV_Relay_6_Status "0=OFF, 1=ON";
CM_ SG_ 170 INV_BMS_Active "0 = BMS Not Active, 1 = BMS Active";
CM_ SG_ 170 INV_BMS_Torque_Limiting "0 = Not Limiting, 1 = Limiting";
CM_ SG_ 170 INV_PWM_Frequency "The current active PWM frequency";
CM_ SG_ 170 INV_Limit_Max_Speed "Indicates that torque is being modified to limit the speed.";
CM_ SG_ 170 INV_Limit_Hot_Spot "Indicates that torque is being limited to limit the hot spot temp";
CM_ SG_ 170 INV_Low_Speed_Limiting "Indicates that motor current is being limited due to low motor electrical frequency.";
CM_ SG_ 170 INV_Rolling_Counter "Rolling Counter value";
CM_ SG_ 170 INV_Limit_Coolant_Derating "0 = Not limiting, 1 = Limiting";
CM_ SG_ 170 INV_Self_Sensing_Assist_Enable "1 = Self Sensing Assist Enabled, 0 = Self Sensing Assist Disabled";
CM_ SG_ 170 INV_Limit_Stall_Burst_Model "0 = Not limiting, 1 = Limiting";
CM_ SG_ 170 INV_Burst_Model_Mode "0 = Stall, 1 = High Speed";
CM_ SG_ 170 INV_Key_Switch_Start_Status "0 = OFF, 1 = ON";
CM_ SG_ 169 INV_Ref_Voltage_12_0 "12V Input Voltage";
CM_ SG_ 169 INV_Ref_Voltage_5_0 "Transducer voltage";
CM_ SG_ 169 INV_Ref_Voltage_2_5 "Internal reference voltage";
CM_ SG_ 169 INV_Ref_Voltage_1_5 "Internal reference voltage";
CM_ SG_ 168 INV_Iq "The measured Iq current";
CM_ SG_ 168 INV_Id "The measured Id current";
CM_ SG_ 168 INV_Vq_ff "The q-axis voltage feedforward";
CM_ SG_ 168 INV_Vd_ff "The d-axis voltage feedforward";
CM_ SG_ 167 INV_VBC_Vq_Voltage "Measured value of the voltage between Phase B and Phase C";
CM_ SG_ 167 INV_VAB_Vd_Voltage "Measured value of the voltage betwen phase A and Phase B";
CM_ SG_ 167 INV_Output_Voltage "The calculated value of the output voltage, in peak line-neutral volts";
CM_ SG_ 167 INV_DC_Bus_Voltage "The actual measured value of the DC bus voltage";
CM_ SG_ 166 INV_DC_Bus_Current "The Calculated DC Bus Current";
CM_ SG_ 166 INV_Phase_C_Current "The measured value of Phase C current";
CM_ SG_ 166 INV_Phase_B_Current "The measured value of Phase B current";
CM_ SG_ 166 INV_Phase_A_Current "The measured value of Phase A current";
CM_ SG_ 165 INV_Delta_Resolver_Filtered "Used in calibration of resolver angle adjustment.";
CM_ SG_ 165 INV_Electrical_Output_Frequency "The actual electrical frequency of the inverter";
CM_ SG_ 165 INV_Motor_Speed "The measured speed of the motor";
CM_ SG_ 165 INV_Motor_Angle_Electrical "The Electrical Angle of the motor as read by the encoder or resolver";
CM_ SG_ 164 INV_Digital_Input_5 "Status of Digital Input #5";
CM_ SG_ 164 INV_Digital_Input_4 "Status of Digital Input #4";
CM_ SG_ 164 INV_Digital_Input_3 "Status of Digital Input #3";
CM_ SG_ 164 INV_Digital_Input_2 "Status of Digital Input #2";
CM_ SG_ 164 INV_Digital_Input_1 "Status of Digital Input #1";
CM_ SG_ 164 INV_Digital_Input_6 "Status of Digital Input #6";
CM_ SG_ 164 INV_Digital_Input_7 "Status of Digital Input #7";
CM_ SG_ 164 INV_Digital_Input_8 "Status of Digital Input #8";
CM_ SG_ 163 INV_Analog_Input_1 "Voltage on Analog Input #1";
CM_ SG_ 163 INV_Analog_Input_2 "Voltage on Analog Input #2";
CM_ SG_ 163 INV_Analog_Input_3 "Voltage on Analog Input #3";
CM_ SG_ 163 INV_Analog_Input_4 "Voltage on Analog Input #4";
CM_ SG_ 163 INV_Analog_Input_5 "Voltage on Analog Input #5";
CM_ SG_ 163 INV_Analog_Input_6 "Voltage on Analog Input #6";
CM_ SG_ 162 INV_Torque_Shudder "Shudder compensation value of torque";
CM_ SG_ 162 INV_Motor_Temp "Motor Temperature Sensor";
CM_ SG_ 162 INV_Hot_Spot_Temp "Estimated inverter hot spot temperature";
CM_ SG_ 162 INV_Coolant_Temp "Estimated Coolant Temperature";
CM_ SG_ 161 INV_RTD2_Temperature "RTD input 2 (PT1000) Temperature";
CM_ SG_ 161 INV_RTD1_Temperature "RTD input 1 (PT1000) Temperature";
CM_ SG_ 161 INV_Control_Board_Temp "Control Board Temperature";
CM_ SG_ 161 INV_Stall_Burst_Model_Temp "Hottest temperature estimated from the stall burst thermal model feature";
CM_ SG_ 160 INV_Gate_Driver_Board_Temp "Gate Driver Board Temperature";
CM_ SG_ 160 INV_Module_C_Temp "IGBT Module C Temperature";
CM_ SG_ 160 INV_Module_B_Temp "IGBT Module B Temperature";
CM_ SG_ 160 INV_Module_A_Temp "IGBT Module A Temperature";
CM_ BO_ 514 "Sent by BMS";
CM_ SG_ 514 BMS_Max_Discharge_Current "Maximum discharge current from BMS";
CM_ SG_ 514 BMS_Max_Charge_Current "Maximum charge current from BMS";
CM_ BO_ 176 "To enable fast message set CAN ACTIVE MSGS HI WORD to 0xFFFE.  Setting to default value of 0xFFFF will disable the fast message.";
CM_ SG_ 176 INV_Fast_Torque_Command "The commanded torque";
CM_ SG_ 176 INV_Fast_Torque_Feedback "The estimated torque";
CM_ SG_ 176 INV_Fast_Motor_Speed "Motor speed";
CM_ SG_ 176 INV_Fast_DC_Bus_Voltage "DC Bus Voltage";
CM_ BO_ 1712 "This ID Transmits at 8 ms.";
CM_ BO_ 1713 "This ID Transmits at 104 ms.";
CM_ BO_ 2000 "Contains Pedal Info";
CM_ BO_ 2003 "Precharge command from front ECU to rear";
BA_DEF_ BO_  "GenMsgCycleTime" INT 0 100000;
BA_DEF_  "BusType" STRING ;
BA_DEF_DEF_  "GenMsgCycleTime" 0;
BA_DEF_DEF_  "BusType" "CAN";
BA_ "GenMsgCycleTime" BO_ 172 10;
BA_ "GenMsgCycleTime" BO_ 192 10;
BA_ "GenMsgCycleTime" BO_ 171 100;
BA_ "GenMsgCycleTime" BO_ 170 100;
BA_ "GenMsgCycleTime" BO_ 169 100;
BA_ "GenMsgCycleTime" BO_ 168 10;
BA_ "GenMsgCycleTime" BO_ 167 10;
BA_ "GenMsgCycleTime" BO_ 166 10;
BA_ "GenMsgCycleTime" BO_ 165 10;
BA_ "GenMsgCycleTime" BO_ 164 10;
BA_ "GenMsgCycleTime" BO_ 163 10;
BA_ "GenMsgCycleTime" BO_ 162 100;
BA_ "GenMsgCycleTime" BO_ 161 100;
BA_ "GenMsgCycleTime" BO_ 160 100;
BA_ "GenMsgCycleTime" BO_ 176 3;
BA_ "GenMsgCycleTime" BO_ 2003 100;
VAL_ 192 VCU_INV_Inverter_Enable 0 "Turn the inverter OFF" 1 "Turn the Inverter ON" ;
VAL_ 192 VCU_INV_Direction_Command 0 "CW" 1 "CCW" ;
VAL_ 192 VCU_INV_Inverter_Discharge 0 "Discharge Disable" 1 "Discharge Enable (if EEPROM parameter is set)" ;
VAL_ 170 INV_Inverter_State 0 "Power up" 1 "Stop" 2 "Open Loop" 3 "Closed Loop" 4 "Internal State" 5 "Internal State" 6 "Internal State" 7 "Internal State" 8 "Idle Run" 9 "Idle Stop" 10 "Internal State" 11 "Intern State" 12 "Internal State" ;
VAL_ 170 INV_VSM_State 0 "VSM Start State" 1 "Pre-Charge Init state" 2 "pre-charge active state" 3 "pre-charge complete state" 4 "VSM wait state" 5 "VSM ready state" 6 "Motor Running State" 7 "blink fault code state" 14 "Shutdown state for Key Switch Mode 1" 15 "Reset the inverter" ;
VAL_ 170 INV_Inverter_Discharge_State 0 "Disabled" 1 "Enabled" 2 "Speed Check" 3 "Active" 4 "Complete" 5 "Error" 6 "Override" 7 "Timeout" ;
VAL_ 170 INV_Limit_Stall_Burst_Model 0 "Not Limiting" 1 "Limiting" ;
VAL_ 170 INV_Burst_Model_Mode 0 "Stall" 1 "High Speed" ;
VAL_ 2000 sensorPlausibility 0 "OK" 1 "Plausability Fault" ;
VAL_ 2001 HSD1State 0 "OFF" 1 "ON" ;
VAL_ 2001 HSD2State 0 "OFF" 1 "ON" ;
VAL_ 2001 HSD3State 0 "OFF" 1 "ON" ;
VAL_ 2001 HSD4State 0 "OFF" 1 "ON" ;
VAL_ 2001 HSD5State 0 "OFF" 1 "ON" ;
VAL_ 2001 HSD6State 0 "OFF" 1 "ON" ;
VAL_ 2001 HSD7State 0 "OFF" 1 "ON" ;
VAL_ 2002 State 0 "START" 1 "PRECHARGE_ENABLE" 2 "PRECHARGE_OK" 3 "STARTUP_DELAY" 4 "DRIVE" 5 "PRECHARGE_ERROR" 6 "DEVICE_FAULT" ;
VAL_ 2003 Precharge_Enable 1 "ON" 0 "OFF" ;
VAL_ 2003 Precharge_OK 0 "OFF" 1 "ON" ;
VAL_ 2004 HSD1 0 "OFF" 1 "ON" ;
VAL_ 2004 HSD2 0 "OFF" 1 "ON" ;
VAL_ 2004 HSD3 0 "OFF" 1 "ON" ;
VAL_ 2004 HSD4 0 "OFF" 1 "ON" ;
VAL_ 2004 HSD5 0 "OFF" 1 "ON" ;
VAL_ 2004 HSD6 0 "OFF" 1 "ON" ;
VAL_ 2004 HSD7 0 "OFF" 1 "ON" ;
